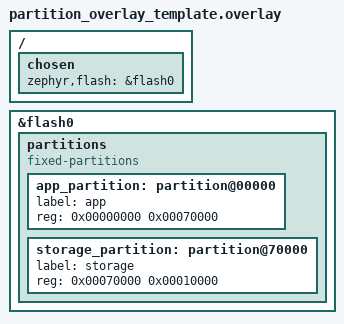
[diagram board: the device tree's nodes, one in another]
/*
 * Template fixed-partitions overlay for app + NVS storage.
 * Adjust addresses/sizes for your target flash map.
 */

/ {
    chosen {
        zephyr,flash = &flash0;
    };
};

&flash0 {
    partitions {
        compatible = "fixed-partitions";
        #address-cells = <1>;
        #size-cells = <1>;

        app_partition: partition@00000 {
            label = "app";
            reg = <0x00000000 0x00070000>;
        };

        storage_partition: partition@70000 {
            label = "storage";
            reg = <0x00070000 0x00010000>;
        };
    };
};
